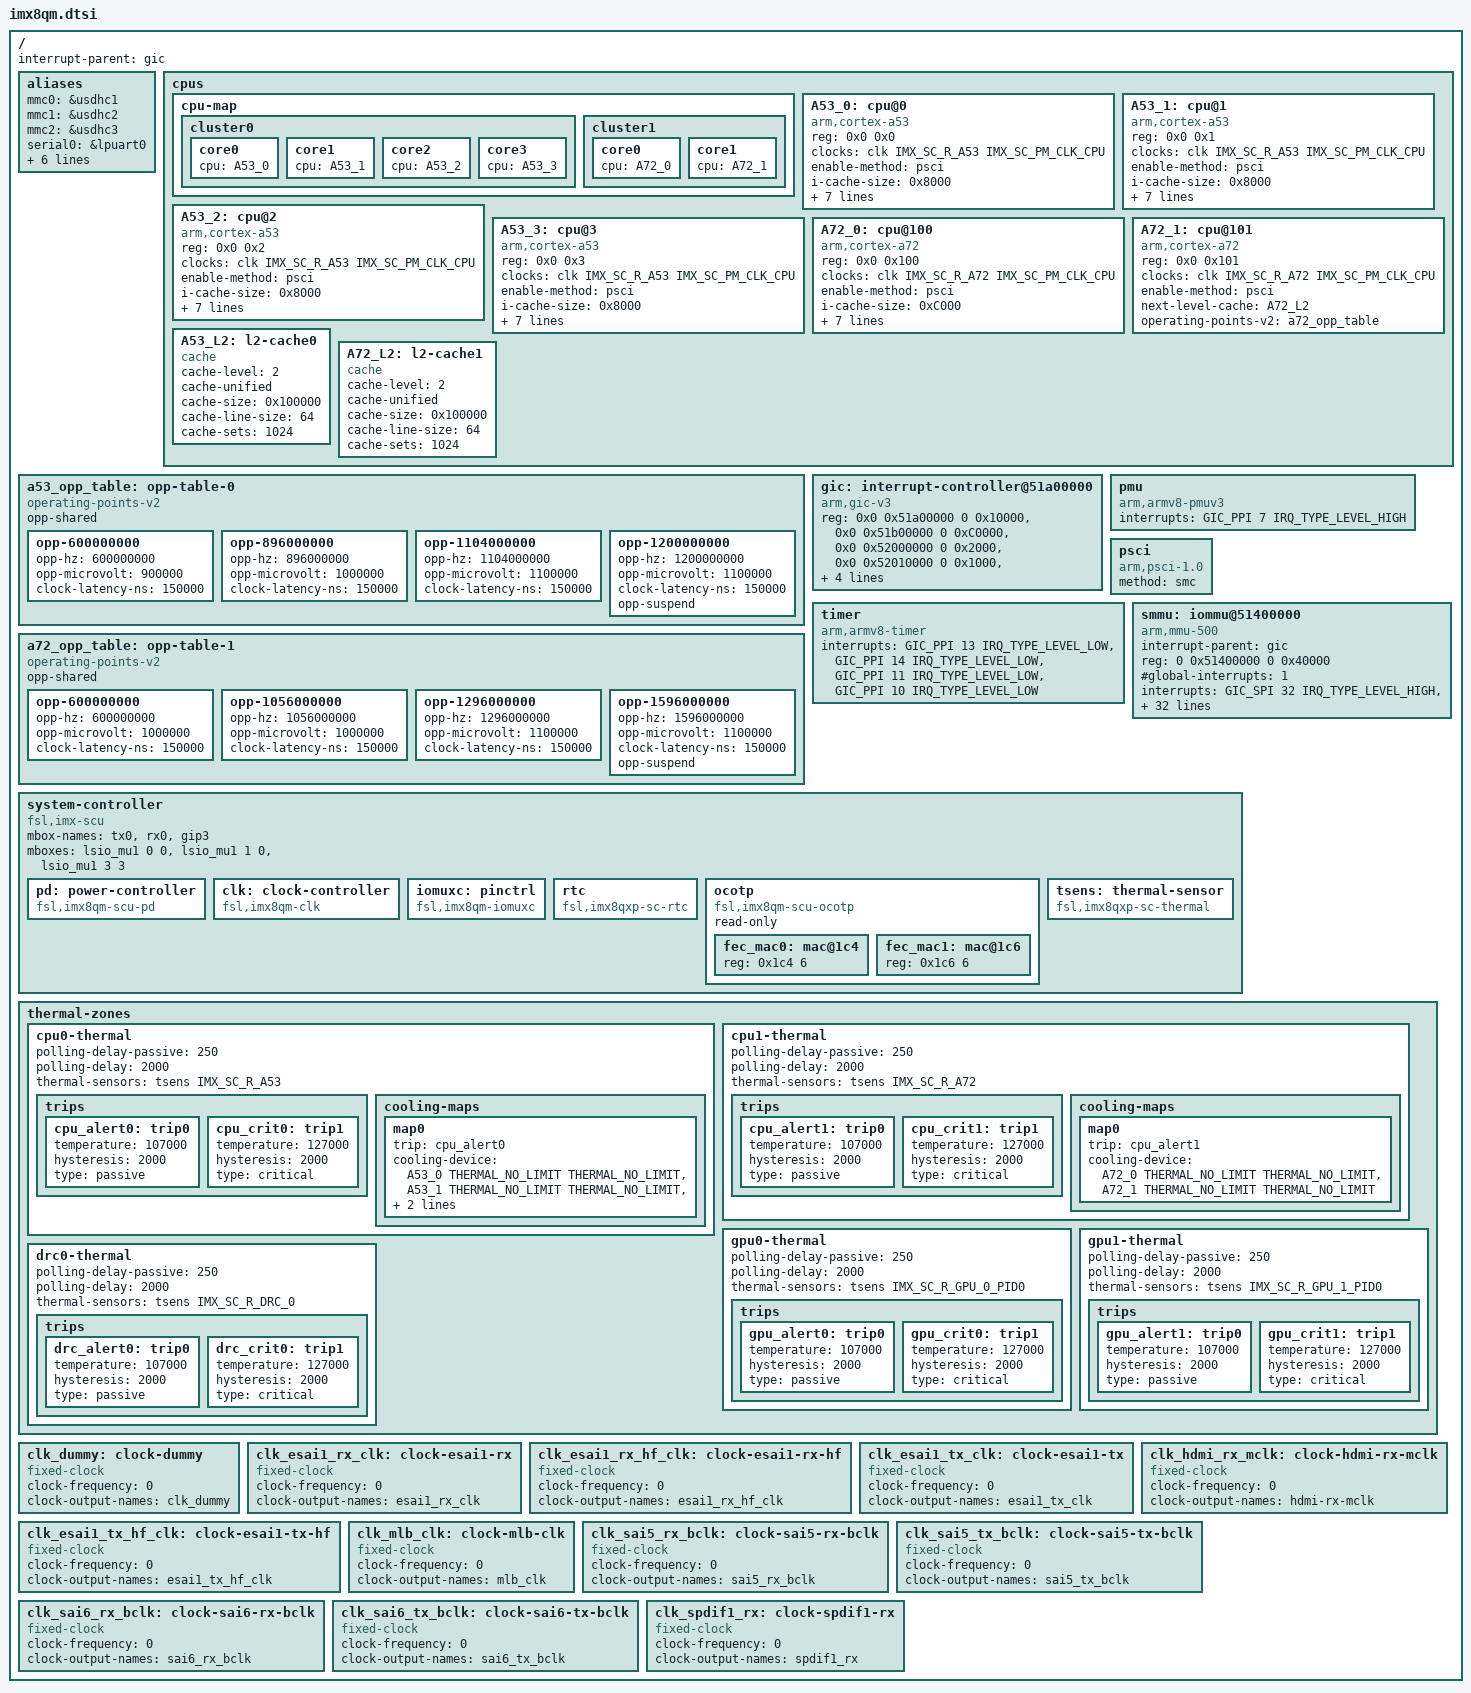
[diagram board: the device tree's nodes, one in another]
// SPDX-License-Identifier: GPL-2.0+
/*
 * Copyright 2018-2019 NXP
 *	Dong Aisheng <aisheng.dong@nxp.com>
 */

#include <dt-bindings/clock/imx8-lpcg.h>
#include <dt-bindings/firmware/imx/rsrc.h>
#include <dt-bindings/gpio/gpio.h>
#include <dt-bindings/interrupt-controller/arm-gic.h>
#include <dt-bindings/pinctrl/pads-imx8qm.h>
#include <dt-bindings/thermal/thermal.h>

/ {
	interrupt-parent = <&gic>;
	#address-cells = <2>;
	#size-cells = <2>;

	aliases {
		mmc0 = &usdhc1;
		mmc1 = &usdhc2;
		mmc2 = &usdhc3;
		serial0 = &lpuart0;
		serial1 = &lpuart1;
		serial2 = &lpuart2;
		serial3 = &lpuart3;
		vpu-core0 = &vpu_core0;
		vpu-core1 = &vpu_core1;
		vpu-core2 = &vpu_core2;
	};

	cpus {
		#address-cells = <2>;
		#size-cells = <0>;

		cpu-map {
			cluster0 {
				core0 {
					cpu = <&A53_0>;
				};
				core1 {
					cpu = <&A53_1>;
				};
				core2 {
					cpu = <&A53_2>;
				};
				core3 {
					cpu = <&A53_3>;
				};
			};

			cluster1 {
				core0 {
					cpu = <&A72_0>;
				};
				core1 {
					cpu = <&A72_1>;
				};
			};
		};

		A53_0: cpu@0 {
			device_type = "cpu";
			compatible = "arm,cortex-a53";
			reg = <0x0 0x0>;
			clocks = <&clk IMX_SC_R_A53 IMX_SC_PM_CLK_CPU>;
			enable-method = "psci";
			i-cache-size = <0x8000>;
			i-cache-line-size = <64>;
			i-cache-sets = <256>;
			d-cache-size = <0x8000>;
			d-cache-line-size = <64>;
			d-cache-sets = <128>;
			next-level-cache = <&A53_L2>;
			operating-points-v2 = <&a53_opp_table>;
			#cooling-cells = <2>;
		};

		A53_1: cpu@1 {
			device_type = "cpu";
			compatible = "arm,cortex-a53";
			reg = <0x0 0x1>;
			clocks = <&clk IMX_SC_R_A53 IMX_SC_PM_CLK_CPU>;
			enable-method = "psci";
			i-cache-size = <0x8000>;
			i-cache-line-size = <64>;
			i-cache-sets = <256>;
			d-cache-size = <0x8000>;
			d-cache-line-size = <64>;
			d-cache-sets = <128>;
			next-level-cache = <&A53_L2>;
			operating-points-v2 = <&a53_opp_table>;
			#cooling-cells = <2>;
		};

		A53_2: cpu@2 {
			device_type = "cpu";
			compatible = "arm,cortex-a53";
			reg = <0x0 0x2>;
			clocks = <&clk IMX_SC_R_A53 IMX_SC_PM_CLK_CPU>;
			enable-method = "psci";
			i-cache-size = <0x8000>;
			i-cache-line-size = <64>;
			i-cache-sets = <256>;
			d-cache-size = <0x8000>;
			d-cache-line-size = <64>;
			d-cache-sets = <128>;
			next-level-cache = <&A53_L2>;
			operating-points-v2 = <&a53_opp_table>;
			#cooling-cells = <2>;
		};

		A53_3: cpu@3 {
			device_type = "cpu";
			compatible = "arm,cortex-a53";
			reg = <0x0 0x3>;
			clocks = <&clk IMX_SC_R_A53 IMX_SC_PM_CLK_CPU>;
			enable-method = "psci";
			i-cache-size = <0x8000>;
			i-cache-line-size = <64>;
			i-cache-sets = <256>;
			d-cache-size = <0x8000>;
			d-cache-line-size = <64>;
			d-cache-sets = <128>;
			next-level-cache = <&A53_L2>;
			operating-points-v2 = <&a53_opp_table>;
			#cooling-cells = <2>;
		};

		A72_0: cpu@100 {
			device_type = "cpu";
			compatible = "arm,cortex-a72";
			reg = <0x0 0x100>;
			clocks = <&clk IMX_SC_R_A72 IMX_SC_PM_CLK_CPU>;
			enable-method = "psci";
			i-cache-size = <0xC000>;
			i-cache-line-size = <64>;
			i-cache-sets = <256>;
			d-cache-size = <0x8000>;
			d-cache-line-size = <64>;
			d-cache-sets = <256>;
			next-level-cache = <&A72_L2>;
			operating-points-v2 = <&a72_opp_table>;
			#cooling-cells = <2>;
		};

		A72_1: cpu@101 {
			device_type = "cpu";
			compatible = "arm,cortex-a72";
			reg = <0x0 0x101>;
			clocks = <&clk IMX_SC_R_A72 IMX_SC_PM_CLK_CPU>;
			enable-method = "psci";
			next-level-cache = <&A72_L2>;
			operating-points-v2 = <&a72_opp_table>;
			#cooling-cells = <2>;
		};

		A53_L2: l2-cache0 {
			compatible = "cache";
			cache-level = <2>;
			cache-unified;
			cache-size = <0x100000>;
			cache-line-size = <64>;
			cache-sets = <1024>;
		};

		A72_L2: l2-cache1 {
			compatible = "cache";
			cache-level = <2>;
			cache-unified;
			cache-size = <0x100000>;
			cache-line-size = <64>;
			cache-sets = <1024>;
		};
	};

	a53_opp_table: opp-table-0 {
		compatible = "operating-points-v2";
		opp-shared;

		opp-600000000 {
			opp-hz = /bits/ 64 <600000000>;
			opp-microvolt = <900000>;
			clock-latency-ns = <150000>;
		};

		opp-896000000 {
			opp-hz = /bits/ 64 <896000000>;
			opp-microvolt = <1000000>;
			clock-latency-ns = <150000>;
		};

		opp-1104000000 {
			opp-hz = /bits/ 64 <1104000000>;
			opp-microvolt = <1100000>;
			clock-latency-ns = <150000>;
		};

		opp-1200000000 {
			opp-hz = /bits/ 64 <1200000000>;
			opp-microvolt = <1100000>;
			clock-latency-ns = <150000>;
			opp-suspend;
		};
	};

	a72_opp_table: opp-table-1 {
		compatible = "operating-points-v2";
		opp-shared;

		opp-600000000 {
			opp-hz = /bits/ 64 <600000000>;
			opp-microvolt = <1000000>;
			clock-latency-ns = <150000>;
		};

		opp-1056000000 {
			opp-hz = /bits/ 64 <1056000000>;
			opp-microvolt = <1000000>;
			clock-latency-ns = <150000>;
		};

		opp-1296000000 {
			opp-hz = /bits/ 64 <1296000000>;
			opp-microvolt = <1100000>;
			clock-latency-ns = <150000>;
		};

		opp-1596000000 {
			opp-hz = /bits/ 64 <1596000000>;
			opp-microvolt = <1100000>;
			clock-latency-ns = <150000>;
			opp-suspend;
		};
	};

	gic: interrupt-controller@51a00000 {
		compatible = "arm,gic-v3";
		reg = <0x0 0x51a00000 0 0x10000>, /* GIC Dist */
		      <0x0 0x51b00000 0 0xC0000>, /* GICR */
		      <0x0 0x52000000 0 0x2000>,  /* GICC */
		      <0x0 0x52010000 0 0x1000>,  /* GICH */
		      <0x0 0x52020000 0 0x20000>; /* GICV */
		#interrupt-cells = <3>;
		interrupt-controller;
		interrupts = <GIC_PPI 9 IRQ_TYPE_LEVEL_HIGH>;
		interrupt-parent = <&gic>;
	};

	pmu {
		compatible = "arm,armv8-pmuv3";
		interrupts = <GIC_PPI 7 IRQ_TYPE_LEVEL_HIGH>;
	};

	psci {
		compatible = "arm,psci-1.0";
		method = "smc";
	};

	timer {
		compatible = "arm,armv8-timer";
		interrupts = <GIC_PPI 13 IRQ_TYPE_LEVEL_LOW>, /* Physical Secure */
			     <GIC_PPI 14 IRQ_TYPE_LEVEL_LOW>, /* Physical Non-Secure */
			     <GIC_PPI 11 IRQ_TYPE_LEVEL_LOW>, /* Virtual */
			     <GIC_PPI 10 IRQ_TYPE_LEVEL_LOW>; /* Hypervisor */
	};

	smmu: iommu@51400000 {
		compatible = "arm,mmu-500";
		interrupt-parent = <&gic>;
		reg = <0 0x51400000 0 0x40000>;
		#global-interrupts = <1>;
		#iommu-cells = <2>;
		interrupts = <GIC_SPI 32 IRQ_TYPE_LEVEL_HIGH>,
			     <GIC_SPI 32 IRQ_TYPE_LEVEL_HIGH>,
			     <GIC_SPI 32 IRQ_TYPE_LEVEL_HIGH>,
			     <GIC_SPI 32 IRQ_TYPE_LEVEL_HIGH>,
			     <GIC_SPI 32 IRQ_TYPE_LEVEL_HIGH>,
			     <GIC_SPI 32 IRQ_TYPE_LEVEL_HIGH>,
			     <GIC_SPI 32 IRQ_TYPE_LEVEL_HIGH>,
			     <GIC_SPI 32 IRQ_TYPE_LEVEL_HIGH>,
			     <GIC_SPI 32 IRQ_TYPE_LEVEL_HIGH>,
			     <GIC_SPI 32 IRQ_TYPE_LEVEL_HIGH>,
			     <GIC_SPI 32 IRQ_TYPE_LEVEL_HIGH>,
			     <GIC_SPI 32 IRQ_TYPE_LEVEL_HIGH>,
			     <GIC_SPI 32 IRQ_TYPE_LEVEL_HIGH>,
			     <GIC_SPI 32 IRQ_TYPE_LEVEL_HIGH>,
			     <GIC_SPI 32 IRQ_TYPE_LEVEL_HIGH>,
			     <GIC_SPI 32 IRQ_TYPE_LEVEL_HIGH>,
			     <GIC_SPI 32 IRQ_TYPE_LEVEL_HIGH>,
			     <GIC_SPI 32 IRQ_TYPE_LEVEL_HIGH>,
			     <GIC_SPI 32 IRQ_TYPE_LEVEL_HIGH>,
			     <GIC_SPI 32 IRQ_TYPE_LEVEL_HIGH>,
			     <GIC_SPI 32 IRQ_TYPE_LEVEL_HIGH>,
			     <GIC_SPI 32 IRQ_TYPE_LEVEL_HIGH>,
			     <GIC_SPI 32 IRQ_TYPE_LEVEL_HIGH>,
			     <GIC_SPI 32 IRQ_TYPE_LEVEL_HIGH>,
			     <GIC_SPI 32 IRQ_TYPE_LEVEL_HIGH>,
			     <GIC_SPI 32 IRQ_TYPE_LEVEL_HIGH>,
			     <GIC_SPI 32 IRQ_TYPE_LEVEL_HIGH>,
			     <GIC_SPI 32 IRQ_TYPE_LEVEL_HIGH>,
			     <GIC_SPI 32 IRQ_TYPE_LEVEL_HIGH>,
			     <GIC_SPI 32 IRQ_TYPE_LEVEL_HIGH>,
			     <GIC_SPI 32 IRQ_TYPE_LEVEL_HIGH>,
			     <GIC_SPI 32 IRQ_TYPE_LEVEL_HIGH>,
			     <GIC_SPI 32 IRQ_TYPE_LEVEL_HIGH>;
	};

	system-controller {
		compatible = "fsl,imx-scu";
		mbox-names = "tx0",
			     "rx0",
			     "gip3";
		mboxes = <&lsio_mu1 0 0
			  &lsio_mu1 1 0
			  &lsio_mu1 3 3>;

		pd: power-controller {
			compatible = "fsl,imx8qm-scu-pd", "fsl,scu-pd";
			#power-domain-cells = <1>;
		};

		clk: clock-controller {
			compatible = "fsl,imx8qm-clk", "fsl,scu-clk";
			#clock-cells = <2>;
		};

		iomuxc: pinctrl {
			compatible = "fsl,imx8qm-iomuxc";
		};

		rtc: rtc {
			compatible = "fsl,imx8qxp-sc-rtc";
		};

		ocotp: ocotp {
			compatible = "fsl,imx8qm-scu-ocotp";
			#address-cells = <1>;
			#size-cells = <1>;
			read-only;

			fec_mac0: mac@1c4 {
				reg = <0x1c4 6>;
			};

			fec_mac1: mac@1c6 {
				reg = <0x1c6 6>;
			};
		};

		tsens: thermal-sensor {
			compatible = "fsl,imx8qxp-sc-thermal", "fsl,imx-sc-thermal";
			#thermal-sensor-cells = <1>;
		};
	};

	thermal-zones {
		cpu0-thermal {
			polling-delay-passive = <250>;
			polling-delay = <2000>;
			thermal-sensors = <&tsens IMX_SC_R_A53>;

			trips {
				cpu_alert0: trip0 {
					temperature = <107000>;
					hysteresis = <2000>;
					type = "passive";
				};

				cpu_crit0: trip1 {
					temperature = <127000>;
					hysteresis = <2000>;
					type = "critical";
				};
			};

			cooling-maps {
				map0 {
					trip = <&cpu_alert0>;
					cooling-device =
						<&A53_0 THERMAL_NO_LIMIT THERMAL_NO_LIMIT>,
						<&A53_1 THERMAL_NO_LIMIT THERMAL_NO_LIMIT>,
						<&A53_2 THERMAL_NO_LIMIT THERMAL_NO_LIMIT>,
						<&A53_3 THERMAL_NO_LIMIT THERMAL_NO_LIMIT>;
				};
			};
		};

		cpu1-thermal {
			polling-delay-passive = <250>;
			polling-delay = <2000>;
			thermal-sensors = <&tsens IMX_SC_R_A72>;

			trips {
				cpu_alert1: trip0 {
					temperature = <107000>;
					hysteresis = <2000>;
					type = "passive";
				};

				cpu_crit1: trip1 {
					temperature = <127000>;
					hysteresis = <2000>;
					type = "critical";
				};
			};

			cooling-maps {
				map0 {
					trip = <&cpu_alert1>;
					cooling-device =
						<&A72_0 THERMAL_NO_LIMIT THERMAL_NO_LIMIT>,
						<&A72_1 THERMAL_NO_LIMIT THERMAL_NO_LIMIT>;
				};
			};
		};

		gpu0-thermal {
			polling-delay-passive = <250>;
			polling-delay = <2000>;
			thermal-sensors = <&tsens IMX_SC_R_GPU_0_PID0>;

			trips {
				gpu_alert0: trip0 {
					temperature = <107000>;
					hysteresis = <2000>;
					type = "passive";
				};

				gpu_crit0: trip1 {
					temperature = <127000>;
					hysteresis = <2000>;
					type = "critical";
				};
			};
		};

	       gpu1-thermal {
			polling-delay-passive = <250>;
			polling-delay = <2000>;
			thermal-sensors = <&tsens IMX_SC_R_GPU_1_PID0>;

			trips {
				gpu_alert1: trip0 {
					temperature = <107000>;
					hysteresis = <2000>;
					type = "passive";
				};

				gpu_crit1: trip1 {
					temperature = <127000>;
					hysteresis = <2000>;
					type = "critical";
				};
			};
		};

		drc0-thermal {
			polling-delay-passive = <250>;
			polling-delay = <2000>;
			thermal-sensors = <&tsens IMX_SC_R_DRC_0>;

			trips {
				drc_alert0: trip0 {
					temperature = <107000>;
					hysteresis = <2000>;
					type = "passive";
				};

				drc_crit0: trip1 {
					temperature = <127000>;
					hysteresis = <2000>;
					type = "critical";
				};
			};
		};
	};

	clk_dummy: clock-dummy {
		compatible = "fixed-clock";
		#clock-cells = <0>;
		clock-frequency = <0>;
		clock-output-names = "clk_dummy";
	};

	clk_esai1_rx_clk: clock-esai1-rx {
		compatible = "fixed-clock";
		#clock-cells = <0>;
		clock-frequency = <0>;
		clock-output-names = "esai1_rx_clk";
	};

	clk_esai1_rx_hf_clk: clock-esai1-rx-hf {
		compatible = "fixed-clock";
		#clock-cells = <0>;
		clock-frequency = <0>;
		clock-output-names = "esai1_rx_hf_clk";
	};

	clk_esai1_tx_clk: clock-esai1-tx {
		compatible = "fixed-clock";
		#clock-cells = <0>;
		clock-frequency = <0>;
		clock-output-names = "esai1_tx_clk";
	};

	clk_esai1_tx_hf_clk: clock-esai1-tx-hf {
		compatible = "fixed-clock";
		#clock-cells = <0>;
		clock-frequency = <0>;
		clock-output-names = "esai1_tx_hf_clk";
	};

	clk_hdmi_rx_mclk: clock-hdmi-rx-mclk {
		compatible = "fixed-clock";
		#clock-cells = <0>;
		clock-frequency = <0>;
		clock-output-names = "hdmi-rx-mclk";
	};

	clk_mlb_clk: clock-mlb-clk {
		compatible = "fixed-clock";
		#clock-cells = <0>;
		clock-frequency = <0>;
		clock-output-names = "mlb_clk";
	};

	clk_sai5_rx_bclk: clock-sai5-rx-bclk {
		compatible = "fixed-clock";
		#clock-cells = <0>;
		clock-frequency = <0>;
		clock-output-names = "sai5_rx_bclk";
	};

	clk_sai5_tx_bclk: clock-sai5-tx-bclk {
		compatible = "fixed-clock";
		#clock-cells = <0>;
		clock-frequency = <0>;
		clock-output-names = "sai5_tx_bclk";
	};

	clk_sai6_rx_bclk: clock-sai6-rx-bclk {
		compatible = "fixed-clock";
		#clock-cells = <0>;
		clock-frequency = <0>;
		clock-output-names = "sai6_rx_bclk";
	};

	clk_sai6_tx_bclk: clock-sai6-tx-bclk {
		compatible = "fixed-clock";
		#clock-cells = <0>;
		clock-frequency = <0>;
		clock-output-names = "sai6_tx_bclk";
	};

	clk_spdif1_rx: clock-spdif1-rx {
		compatible = "fixed-clock";
		#clock-cells = <0>;
		clock-frequency = <0>;
		clock-output-names = "spdif1_rx";
	};

	/* sorted in register address */
	#include "imx8-ss-cm41.dtsi"
	#include "imx8-ss-audio.dtsi"
	#include "imx8-ss-vpu.dtsi"
	#include "imx8-ss-gpu0.dtsi"
	#include "imx8-ss-img.dtsi"
	#include "imx8-ss-dma.dtsi"
	#include "imx8-ss-conn.dtsi"
	#include "imx8-ss-lsio.dtsi"
};

#include "imx8qm-ss-img.dtsi"
#include "imx8qm-ss-dma.dtsi"
#include "imx8qm-ss-conn.dtsi"
#include "imx8qm-ss-lsio.dtsi"
#include "imx8qm-ss-audio.dtsi"
